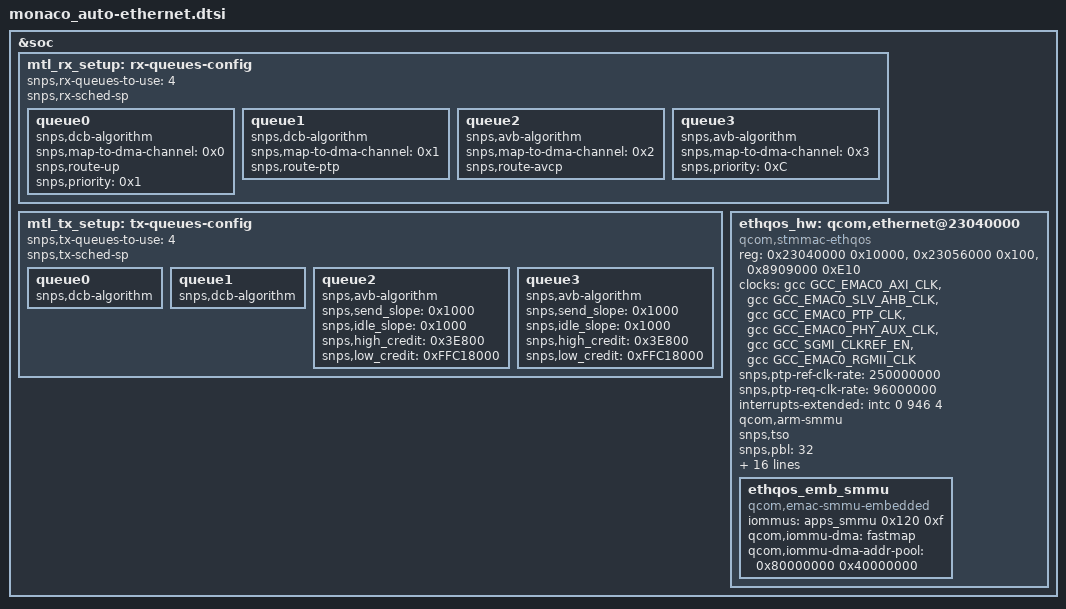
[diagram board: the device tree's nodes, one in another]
&soc {
	mtl_rx_setup: rx-queues-config {
		snps,rx-queues-to-use = <4>;
		snps,rx-sched-sp;

		queue0 {
			snps,dcb-algorithm;
			snps,map-to-dma-channel = <0x0>;
			snps,route-up;
			snps,priority = <0x1>;
		};

		queue1 {
			snps,dcb-algorithm;
			snps,map-to-dma-channel = <0x1>;
			snps,route-ptp;
		};

		queue2 {
			snps,avb-algorithm;
			snps,map-to-dma-channel = <0x2>;
			snps,route-avcp;
		};

		queue3 {
			snps,avb-algorithm;
			snps,map-to-dma-channel = <0x3>;
			snps,priority = <0xC>;
		};
	};

	mtl_tx_setup: tx-queues-config {
		snps,tx-queues-to-use = <4>;
		snps,tx-sched-sp;
		queue0 {
			snps,dcb-algorithm;
		};

		queue1 {
			snps,dcb-algorithm;
		};

		queue2 {
			snps,avb-algorithm;
			snps,send_slope = <0x1000>;
			snps,idle_slope = <0x1000>;
			snps,high_credit = <0x3E800>;
			snps,low_credit = <0xFFC18000>;
		};

		queue3 {
			snps,avb-algorithm;
			snps,send_slope = <0x1000>;
			snps,idle_slope = <0x1000>;
			snps,high_credit = <0x3E800>;
			snps,low_credit = <0xFFC18000>;
		};
	};

	ethqos_hw: qcom,ethernet@23040000 {
		compatible = "qcom,stmmac-ethqos","snps,dwmac-4.20a";
		reg = <0x23040000 0x10000>,
			<0x23056000 0x100>,
			<0x8909000 0xE10>;

		reg-names = "stmmaceth","rgmii","serdes";
		clocks = <&gcc GCC_EMAC0_AXI_CLK>,
		<&gcc GCC_EMAC0_SLV_AHB_CLK>,
		<&gcc GCC_EMAC0_PTP_CLK>,
		<&gcc GCC_EMAC0_PHY_AUX_CLK>,
		<&gcc GCC_SGMI_CLKREF_EN>,
		<&gcc GCC_EMAC0_RGMII_CLK>;
		clock-names = "stmmaceth", "pclk", "ptp_ref", "phyaux","sgmi_ref","rgmii";
		snps,ptp-ref-clk-rate = <250000000>;
		snps,ptp-req-clk-rate = <96000000>;
		interrupts-extended = <&intc 0 946 4>;
		qcom,arm-smmu;

		interrupt-names = "macirq";

		snps,tso;
		snps,pbl = <32>;
		rx-fifo-depth = <16384>;
		tx-fifo-depth = <20480>;

		snps,mtl-rx-config = <&mtl_rx_setup>;
		snps,mtl-tx-config = <&mtl_tx_setup>;

		vreg_rgmii-supply = <&pm7255_a_l4>;
		vreg_emac_phy-supply =  <&pm7255_a_l5>;

		snps,reset-gpios = <&tlmm 31 GPIO_ACTIVE_HIGH>;
		gdsc_emac-supply = <&gcc_emac0_gdsc>;

		phy-mode = "sgmii";
		snps,reset-delays-us = <0 11000 70000>;
		pinctrl-names = "dev-emac-mdc",
				"dev-emac-mdio",
				"dev-emac_phy_reset_state";

		pinctrl-0 = <&emac_mdc>;
		pinctrl-1 = <&emac_mdio>;
		pinctrl-2 = <&emac_phy_reset_state>;

		snps,ps-speed = <1000>;
		pcs-v3;
		gdsc-off-on-suspend;

		ethqos_emb_smmu: ethqos_emb_smmu {
			compatible = "qcom,emac-smmu-embedded";
			iommus = <&apps_smmu 0x120 0xf>;
			qcom,iommu-dma = "fastmap";
			qcom,iommu-dma-addr-pool = <0x80000000 0x40000000>;
		};
	};
};
